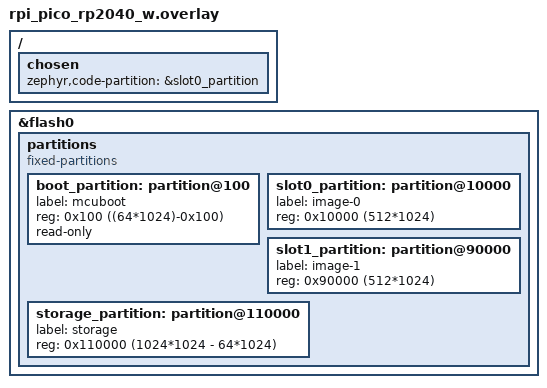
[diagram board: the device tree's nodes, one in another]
/delete-node/ &code_partition;

/ {
    chosen {
		zephyr,code-partition = &slot0_partition;
	};
};

&flash0 {
    partitions {
        compatible = "fixed-partitions";
        #address-cells = <1>;
        #size-cells = <1>;

		boot_partition: partition@100 {
            label = "mcuboot";
            reg = <0x100 ((64*1024)-0x100)>;
            read-only;
        };
        slot0_partition: partition@10000 {
            label = "image-0";
            reg = < 0x10000 (512*1024) >;
        };
        slot1_partition: partition@90000 {
            label = "image-1";
            reg = < 0x90000 (512*1024) >;
        };
        storage_partition: partition@110000 {
            label = "storage";
            reg = < 0x110000 (1024*1024 - 64*1024) >;
        };
    };
};
